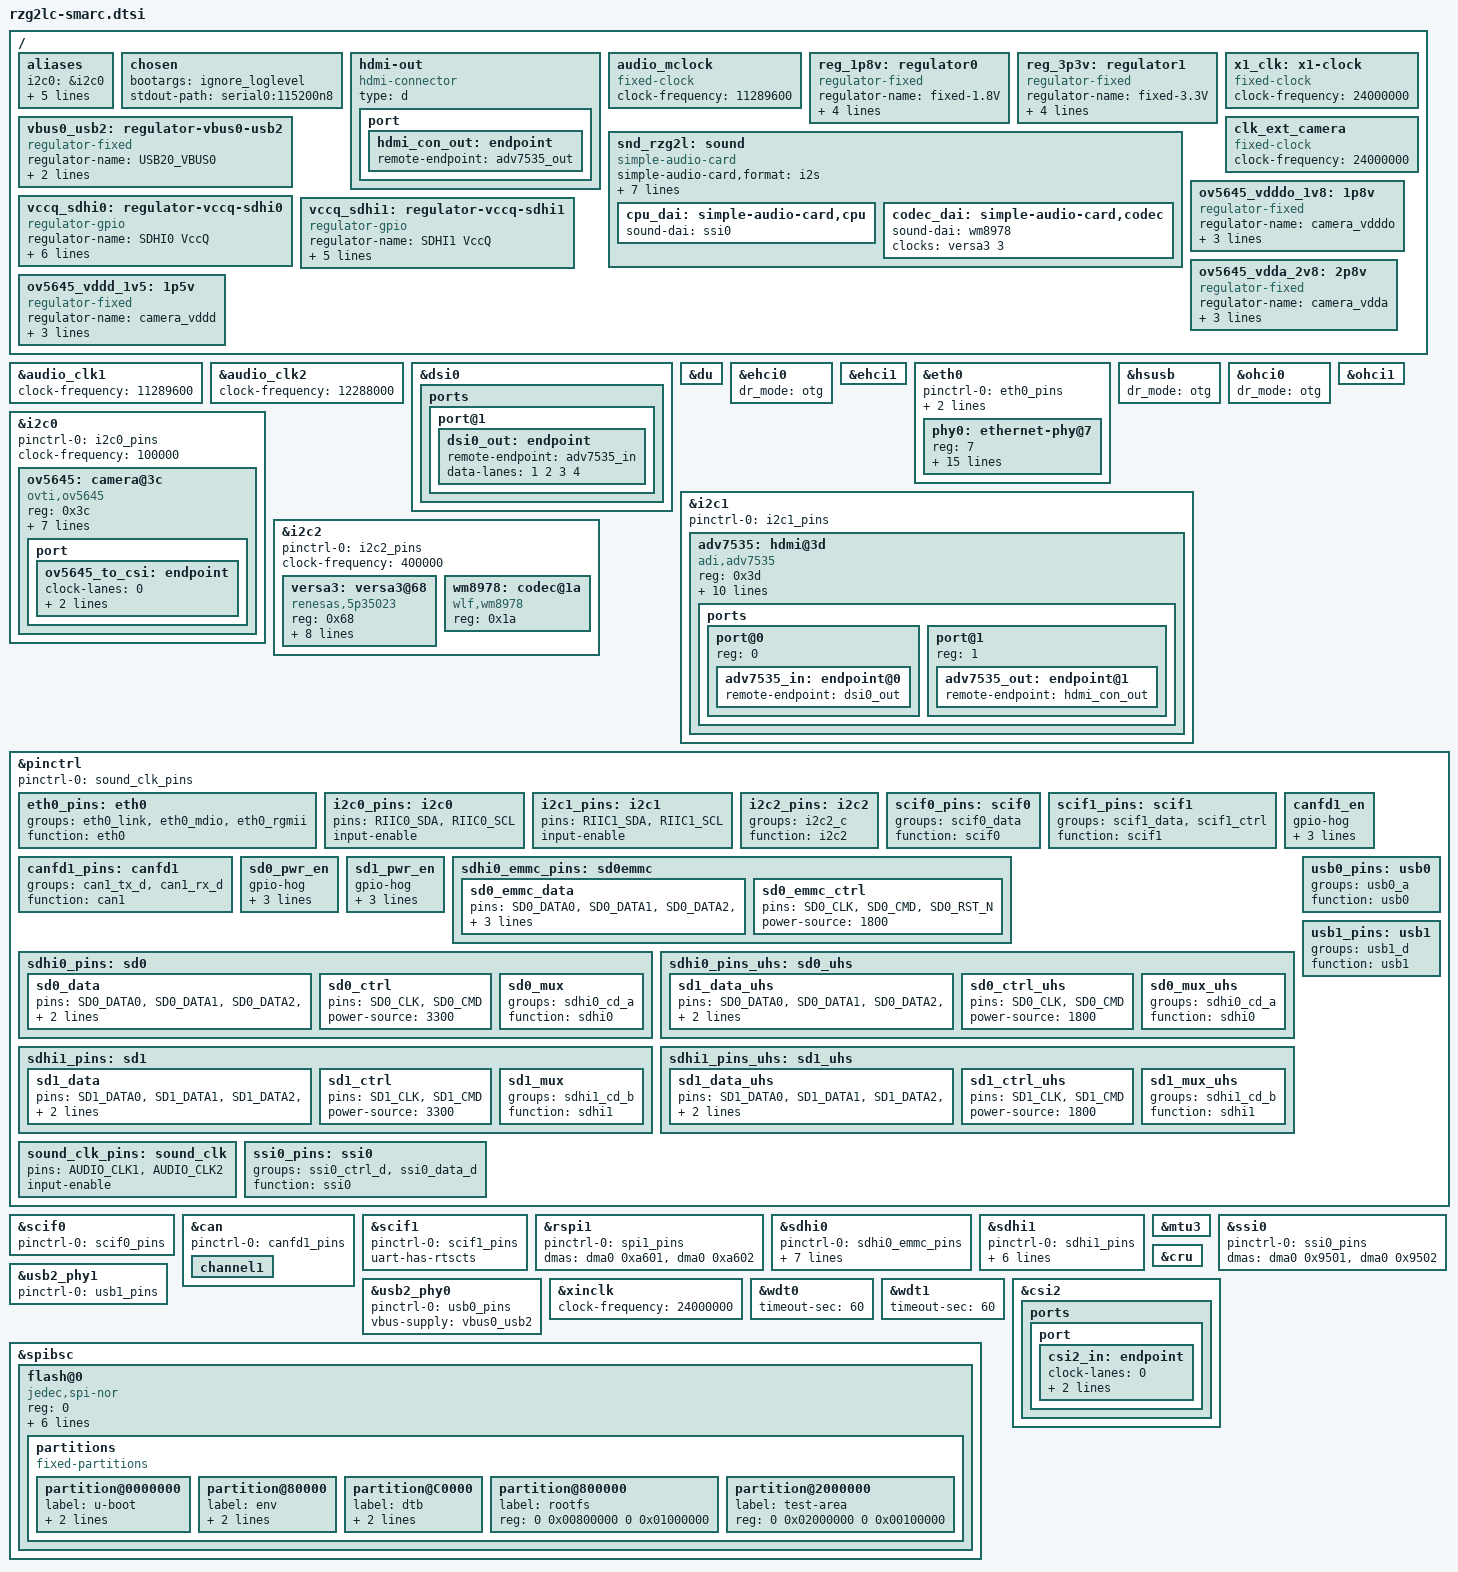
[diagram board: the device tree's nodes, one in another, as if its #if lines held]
// SPDX-License-Identifier: GPL-2.0
/*
 * Device Tree Source for the RZG2LC Evaluation Board Kit
 *
 * Copyright (C) 2021 Renesas Electronics Corp.
 */

#include <dt-bindings/pinctrl/pinctrl-rzg2l.h>
#include <dt-bindings/gpio/gpio.h>

/*
 * SSI-WM8978
 *
 * This command is required when Playback/Capture
 *
 *	amixer cset name='Left Input Mixer L2 Switch' on
 *	amixer cset name='Right Input Mixer R2 Switch' on
 *	amixer cset name='Headphone Playback Volume' 100
 *	amixer cset name='Input PGA Volume' 100
 *	amixer cset name='L2/R2 Boost Volume' 100
 *
 * ADV7535 Audio playback
 *	aplay -D hw:1,0 xxx.wav
 */

/*
 * DIP-Switch SW1 setting
 * 1 : High; 0: Low
 * SW1-2 : SW_SD0_DEV_SEL	(1: eMMC; 0: uSD)
 * SW1-3 : SW_SCIF_CAN		(1: CAN1; 0: SCIF1)
 * SW1-4 : SW_RSPI_CAN 		(1: CAN1; 0: RSPI1)
 * SW1-5 : SW_I2S0_I2S1		(1: I2S2 (HDMI audio); 0: I2S0)
 * Please change below MACROs corespondingly to SW1 setting
 */

#define SW_SD0_DEV_SEL	1
#define SW_SCIF_CAN	0
#if (SW_SCIF_CAN)
/*
 * Due to Hardware routing, SW_RSPI_CAN is always 0 when SW_SCIF_CAN is set to 1
 */
#define SW_RSPI_CAN	0
#else
/*
 * Please choose one of two below setting when SW_SCIF_CAN is set to 0.
 * Default value is 1.
 */
#define SW_RSPI_CAN     1
//#define SW_RSPI_CAN     0
#endif

#define SW_I2S0_I2S1	0

#if (SW_SCIF_CAN & SW_RSPI_CAN)
#error "Can not set 1 to both SW_SCIF_CAN and SW_RSPI_CAN due to Hardware."
#endif

/ {
	aliases {
		i2c0 = &i2c0;
		i2c1 = &i2c1;
		i2c2 = &i2c2;
		serial0 = &scif0;
#if (!SW_SCIF_CAN)
		serial1 = &scif1;
#endif
		ethernet0 = &eth0;
	};

	chosen {
		bootargs = "ignore_loglevel";
		stdout-path = "serial0:115200n8";
	};

	hdmi-out {
		compatible = "hdmi-connector";
		type = "d";

		port {
			hdmi_con_out: endpoint {
				remote-endpoint = <&adv7535_out>;
			};
		};
	};

	audio_mclock: audio_mclock {
		compatible = "fixed-clock";
		#clock-cells = <0>;
		clock-frequency = <11289600>;
	};

	reg_1p8v: regulator0 {
		compatible = "regulator-fixed";
		regulator-name = "fixed-1.8V";
		regulator-min-microvolt = <1800000>;
		regulator-max-microvolt = <1800000>;
		regulator-boot-on;
		regulator-always-on;
	};

	reg_3p3v: regulator1 {
		compatible = "regulator-fixed";

		regulator-name = "fixed-3.3V";
		regulator-min-microvolt = <3300000>;
		regulator-max-microvolt = <3300000>;
		regulator-boot-on;
		regulator-always-on;
	};

	vbus0_usb2: regulator-vbus0-usb2 {
		compatible = "regulator-fixed";

		regulator-name = "USB20_VBUS0";
		regulator-min-microvolt = <5000000>;
		regulator-max-microvolt = <5000000>;
	};

#if (SW_I2S0_I2S1)
	sound_card {
		compatible = "audio-graph-card";
		dais = <&ssi0>;
	};
#else
	snd_rzg2l: sound {
		compatible = "simple-audio-card";
		simple-audio-card,format = "i2s";
		simple-audio-card,bitclock-master = <&cpu_dai>;
		simple-audio-card,frame-master = <&cpu_dai>;
		simple-audio-card,mclk-fs = <256>;

		simple-audio-card,widgets = "Microphone", "Microphone Jack";
		simple-audio-card,routing =
			    "L2", "Mic Bias",
			    "R2", "Mic Bias",
			    "Mic Bias", "Microphone Jack";

		cpu_dai: simple-audio-card,cpu {
			sound-dai = <&ssi0>;
		};

		codec_dai: simple-audio-card,codec {
			sound-dai = <&wm8978>;
			clocks = <&versa3 3>;
		};
	};
#endif

	vccq_sdhi0: regulator-vccq-sdhi0 {
		compatible = "regulator-gpio";

		regulator-name = "SDHI0 VccQ";
		regulator-min-microvolt = <1800000>;
		regulator-max-microvolt = <3300000>;
		states = <3300000 1 1800000 0>;
		regulator-boot-on;
		gpios = <&pinctrl RZG2L_GPIO(39, 0) GPIO_ACTIVE_HIGH>;
		regulator-always-on;
	};

	vccq_sdhi1: regulator-vccq-sdhi1 {
		compatible = "regulator-gpio";

		regulator-name = "SDHI1 VccQ";
		regulator-min-microvolt = <1800000>;
		regulator-max-microvolt = <3300000>;

		gpios = <&pinctrl RZG2L_GPIO(39, 1) GPIO_ACTIVE_HIGH>;

		gpios-states = <1>;
		states = <3300000 1
			  1800000 0>;
	};

	x1_clk: x1-clock {
		compatible = "fixed-clock";
		#clock-cells = <0>;
		clock-frequency = <24000000>;
	};

	clk_ext_camera: clk_ext_camera {
		compatible = "fixed-clock";
		#clock-cells = <0>;
		clock-frequency = <24000000>;
	};

	ov5645_vdddo_1v8: 1p8v {
		compatible = "regulator-fixed";
		regulator-name = "camera_vdddo";
		regulator-min-microvolt = <1800000>;
		regulator-max-microvolt = <1800000>;
		regulator-always-on;
	};

	ov5645_vdda_2v8: 2p8v {
		compatible = "regulator-fixed";
		regulator-name = "camera_vdda";
		regulator-min-microvolt = <2800000>;
		regulator-max-microvolt = <2800000>;
		regulator-always-on;
	};

	ov5645_vddd_1v5: 1p5v {
		compatible = "regulator-fixed";
		regulator-name = "camera_vddd";
		regulator-min-microvolt = <1500000>;
		regulator-max-microvolt = <1500000>;
		regulator-always-on;
	};
};

&audio_clk1{
	clock-frequency = <11289600>;
};

&audio_clk2{
	clock-frequency = <12288000>;
};

&dsi0 {
	status = "okay";

	ports {
		port@1 {
			dsi0_out: endpoint {
				remote-endpoint = <&adv7535_in>;
				data-lanes = <1 2 3 4>;
			};
		};
	};
};

&du {
	status = "okay";
};

&ehci0 {
	dr_mode = "otg";
	status = "okay";
};

&ehci1 {
	status = "okay";
};

&eth0 {
	pinctrl-0 = <&eth0_pins>;
	pinctrl-names = "default";
	phy-handle = <&phy0>;
	phy-mode = "rgmii";
	status = "okay";

	phy0: ethernet-phy@7 {
		reg = <7>;
		rxc-skew-psec = <2400>;
		txc-skew-psec = <2400>;
		rxdv-skew-psec = <0>;
		txdv-skew-psec = <0>;
		rxd0-skew-psec = <0>;
		rxd1-skew-psec = <0>;
		rxd2-skew-psec = <0>;
		rxd3-skew-psec = <0>;
		txd0-skew-psec = <0>;
		txd1-skew-psec = <0>;
		txd2-skew-psec = <0>;
		txd3-skew-psec = <0>;

		interrupt-parent = <&pinctrl>;
		interrupts = <RZG2L_GPIO(0, 0) IRQ_TYPE_EDGE_FALLING>;
	};
};

&hsusb {
	dr_mode = "otg";
	status = "okay";
};

&i2c0 {
	pinctrl-0 = <&i2c0_pins>;
	pinctrl-names = "default";

	clock-frequency = <100000>;
	status = "okay";

	ov5645: camera@3c {
		compatible = "ovti,ov5645";
		reg = <0x3c>;
		clock-names = "xclk";
		clocks = <&clk_ext_camera>;
		clock-frequency = <24000000>;
		vdddo-supply = <&ov5645_vdddo_1v8>;
		vdda-supply = <&ov5645_vdda_2v8>;
		vddd-supply = <&ov5645_vddd_1v5>;
		enable-gpios = <&pinctrl RZG2L_GPIO(0, 1) GPIO_ACTIVE_HIGH>;
		reset-gpios = <&pinctrl RZG2L_GPIO(5, 2) GPIO_ACTIVE_LOW>;

		port {
			ov5645_to_csi: endpoint {
				clock-lanes = <0>;
				data-lanes = <1 2>;
				remote-endpoint = <&csi2_in>;
			};
		};
	};
};

&i2c1 {
	pinctrl-0 = <&i2c1_pins>;
	pinctrl-names = "default";

	status = "okay";

	adv7535: hdmi@3d {
		compatible = "adi,adv7535";
		reg = <0x3d>;

		avdd-supply = <&reg_1p8v>;
		dvdd-supply = <&reg_1p8v>;
		pvdd-supply = <&reg_1p8v>;
		a2vdd-supply = <&reg_1p8v>;
		v3p3-supply = <&reg_3p3v>;
		v1p2-supply = <&reg_1p8v>;

		interrupt-parent = <&pinctrl>;
		interrupts = <RZG2L_GPIO(43, 1) IRQ_TYPE_EDGE_FALLING>;

		adi,dsi-lanes = <4>;
		#sound-dai-cells = <0>;

		ports {
			#address-cells = <1>;
			#size-cells = <0>;

			port@0 {
				reg = <0>;
				adv7535_in: endpoint@0 {
					remote-endpoint = <&dsi0_out>;
				};
			};

			port@1 {
				reg = <1>;
				adv7535_out: endpoint@1 {
					remote-endpoint = <&hdmi_con_out>;
				};
			};

#if (SW_I2S0_I2S1)
			port@2 {
				reg = <2>;
				codec_endpoint: endpoint {
					remote-endpoint = <&i2s2_cpu_endpoint>;
				};
			};
#endif
		};
	};
};

&i2c2 {
	pinctrl-0 = <&i2c2_pins>;
	pinctrl-names = "default";

	clock-frequency = <400000>;
	status = "okay";

	versa3: versa3@68 {
		compatible = "renesas,5p35023";
		reg = <0x68>;
		#clock-cells = <1>;
		clocks = <&x1_clk>;
		clock-names = "x1";
		assigned-clocks = <&versa3 0>,
				   <&versa3 1>,
				   <&versa3 2>,
				   <&versa3 3>,
				   <&versa3 4>,
				   <&versa3 5>;
		assigned-clock-rates =	<12288000>, <25000000>,
					<12000000>, <11289600>,
					<11289600>, <24000000>;
		clock-divider-read-only = <1>, <1>, <1>, <1>, <1>;
		clock-flags = <2176>, <2176>, <2176>, <2052>, <2176>, <2048>;
	};

	wm8978: codec@1a {
		compatible = "wlf,wm8978";
		#sound-dai-cells = <0>;
		reg = <0x1a>;
	};
};

&ohci0 {
	dr_mode = "otg";
	status = "okay";
};

&ohci1 {
	status = "okay";
};

&pinctrl {
	pinctrl-0 = <&sound_clk_pins>;
	pinctrl-names = "default";

	eth0_pins: eth0 {
		groups = "eth0_link", "eth0_mdio", "eth0_rgmii";
		function = "eth0";
	};

	i2c0_pins: i2c0 {
		pins = "RIIC0_SDA", "RIIC0_SCL";
		input-enable;
	};

	i2c1_pins: i2c1 {
		pins = "RIIC1_SDA", "RIIC1_SCL";
		input-enable;
	};

	i2c2_pins: i2c2 {
		groups = "i2c2_c";
		function = "i2c2";
	};

	scif0_pins: scif0 {
		groups = "scif0_data";
		function = "scif0";
	};

#if (SW_SCIF_CAN)
	canfd1_pins: canfd1 {
		groups = "can1_tx_c", "can1_rx_c";
		function = "can1";
	};

	spi1_pins: rspi1 {
		groups = "rspi1_clk_b", "rspi1_data_b", "rspi1_ssl_b";
		function = "rspi1";
	};

#else
	scif1_pins: scif1 {
		groups = "scif1_data", "scif1_ctrl" ;
		function = "scif1";
	};

#if (SW_RSPI_CAN)
	canfd1_en {
		gpio-hog;
		gpios = <RZG2L_GPIO(44, 3) GPIO_ACTIVE_LOW>;
		output-high;
		line-name = "canfd1_en";
	};

	canfd1_pins: canfd1 {
		groups = "can1_tx_d", "can1_rx_d";
		function = "can1";
	};
#else
	spi1_pins: rspi1 {
		groups = "rspi1_clk_b", "rspi1_data_b", "rspi1_ssl_b";
		function = "rspi1";
	};
#endif
#endif

	sd0_pwr_en {
		gpio-hog;
		gpios = <RZG2L_GPIO(40, 2) GPIO_ACTIVE_HIGH>;
		output-high;
		line-name = "sd0_pwr_en";
	};

	sd1_pwr_en {
		gpio-hog;
		gpios = <RZG2L_GPIO(39, 2) GPIO_ACTIVE_HIGH>;
		output-high;
		line-name = "sd1_pwr_en";
	};

	sdhi0_emmc_pins: sd0emmc {
		sd0_emmc_data {
			pins = "SD0_DATA0", "SD0_DATA1", "SD0_DATA2", "SD0_DATA3",
			       "SD0_DATA4", "SD0_DATA5", "SD0_DATA6", "SD0_DATA7";
			power-source  = <1800>;
		};

		sd0_emmc_ctrl {
			pins = "SD0_CLK", "SD0_CMD", "SD0_RST_N";
			power-source  = <1800>;
		};
	};

	sdhi0_pins: sd0 {
		sd0_data {
			pins = "SD0_DATA0", "SD0_DATA1", "SD0_DATA2", "SD0_DATA3";
			power-source  = <3300>;
		};

		sd0_ctrl {
			pins = "SD0_CLK", "SD0_CMD";
			power-source  = <3300>;
		};

		sd0_mux {
			groups = "sdhi0_cd_a";
			function = "sdhi0";
		};
	};

	sdhi0_pins_uhs: sd0_uhs {
		sd1_data_uhs {
			pins = "SD0_DATA0", "SD0_DATA1", "SD0_DATA2", "SD0_DATA3";
			power-source  = <1800>;
		};

		sd0_ctrl_uhs {
			pins = "SD0_CLK", "SD0_CMD";
			power-source  = <1800>;
		};

		sd0_mux_uhs {
			groups = "sdhi0_cd_a";
			function = "sdhi0";
		};
	};

	sdhi1_pins: sd1 {
		sd1_data {
			pins = "SD1_DATA0", "SD1_DATA1", "SD1_DATA2", "SD1_DATA3";
			power-source  = <3300>;
		};

		sd1_ctrl {
			pins = "SD1_CLK", "SD1_CMD";
			power-source  = <3300>;
		};

		sd1_mux {
			groups = "sdhi1_cd_b";
			function = "sdhi1";
		};
	};

	sdhi1_pins_uhs: sd1_uhs {
		sd1_data_uhs {
			pins = "SD1_DATA0", "SD1_DATA1", "SD1_DATA2", "SD1_DATA3";
			power-source  = <1800>;
		};

		sd1_ctrl_uhs {
			pins = "SD1_CLK", "SD1_CMD";
			power-source  = <1800>;
		};

		sd1_mux_uhs {
			groups = "sdhi1_cd_b";
			function = "sdhi1";
		};
	};

	sound_clk_pins: sound_clk {
		pins = "AUDIO_CLK1", "AUDIO_CLK2";
		input-enable;
	};

	ssi0_pins: ssi0 {
		groups = "ssi0_ctrl_d", "ssi0_data_d";
		function = "ssi0";
	};

	/* USB Channel 0 */
	usb0_pins: usb0 {
		groups = "usb0_a";
		function = "usb0";
	};

	/* USB Channel 1 */
	usb1_pins: usb1 {
		groups = "usb1_d";
		function = "usb1";
	};
};

&scif0 {
	pinctrl-0 = <&scif0_pins>;
	pinctrl-names = "default";
	status = "okay";
};

#if ((SW_SCIF_CAN) || (SW_RSPI_CAN))
&can {
	pinctrl-0 = <&canfd1_pins>;
	pinctrl-names = "default";
	status = "okay";

	channel1 {
		status = "okay";
	};
};
#endif

#if (!SW_SCIF_CAN)
&scif1 {
	pinctrl-0 = <&scif1_pins>;
	pinctrl-names = "default";
	uart-has-rtscts;
	status = "okay";
};
#endif

#if ((!SW_RSPI_CAN) || SW_SCIF_CAN)
&rspi1 {
	pinctrl-0 = <&spi1_pins>;
	pinctrl-names = "default";
	status = "okay";
	dmas = <&dma0 0xa601>,
	       <&dma0 0xa602>;
	dma-names = "tx", "rx";
};
#endif

#if (SW_SD0_DEV_SEL)
&sdhi0 {
	pinctrl-0 = <&sdhi0_emmc_pins>;
	pinctrl-1 = <&sdhi0_emmc_pins>;
	pinctrl-names = "default", "state_uhs";

	vmmc-supply = <&reg_3p3v>;
	vqmmc-supply = <&reg_1p8v>;
	bus-width = <8>;
	mmc-hs200-1_8v;
	non-removable;
	fixed-emmc-driver-type = <1>;
	status = "okay";
};
#else
&sdhi0 {
	pinctrl-0 = <&sdhi0_pins>;
	pinctrl-1 = <&sdhi0_pins_uhs>;
	pinctrl-names = "default", "state_uhs";

	vmmc-supply = <&reg_3p3v>;
	vqmmc-supply = <&vccq_sdhi0>;

	bus-width = <4>;
	sd-uhs-sdr50;
	sd-uhs-sdr104;
	status = "okay";
};
#endif

&sdhi1 {
	pinctrl-0 = <&sdhi1_pins>;
	pinctrl-1 = <&sdhi1_pins_uhs>;
	pinctrl-names = "default", "state_uhs";

	vmmc-supply = <&reg_3p3v>;
	vqmmc-supply = <&vccq_sdhi1>;

	bus-width = <4>;
	sd-uhs-sdr50;
	sd-uhs-sdr104;
	status = "okay";
};

&mtu3 {
	status = "okay";
};

&ssi0 {
	pinctrl-0 = <&ssi0_pins>;
	pinctrl-names = "default";

	dmas = <&dma0 0x9501>,
	       <&dma0 0x9502>;
	dma-names = "tx", "rx";
	status = "okay";
#if (SW_I2S0_I2S1)
	ports {
		i2s2_port0: port@0 {
			i2s2_cpu_endpoint: endpoint {
				remote-endpoint = <&codec_endpoint>;
				dai-format = "i2s";
			};
		};
	};

#endif
};

&usb2_phy0 {
	pinctrl-0 = <&usb0_pins>;
	pinctrl-names = "default";

	vbus-supply = <&vbus0_usb2>;
	status = "okay";
};

&usb2_phy1 {
	pinctrl-0 = <&usb1_pins>;
	pinctrl-names = "default";

	status = "okay";
};

&xinclk {
	clock-frequency = <24000000>;
};

&wdt0 {
	status = "okay";
	timeout-sec = <60>;
};

&wdt1 {
	status = "okay";
	timeout-sec = <60>;
};

&spibsc {
status = "okay";

	flash@0 {
		compatible = "jedec,spi-nor";
		reg = <0>;
		spi-max-frequency = <30000000>;

		spi-tx-bus-width = <1>;
		spi-rx-bus-width = <1>;

		/* SPI Mode 3 */
		spi-cpol;
		spi-cpha;
		m25p,fast-read;
		partitions {
			compatible = "fixed-partitions";
			#address-cells = <2>;
			#size-cells = <2>;

			partition@0000000 {
				label = "u-boot";
				reg = <0 0x00000000 0 0x80000>;
				read-only;
			};
			partition@80000 {
				label = "env";
				reg = <0 0x00080000 0 0x40000>;
				read-only;
			};
			partition@C0000 {
				label = "dtb";
				reg = <0 0x000C0000 0 0x40000>;
				read-only;
			};
			partition@800000 {
				label = "rootfs";
				/* 16MB @ 8MB offset in SPI Flash */
				reg = <0 0x00800000 0 0x01000000>;
			};
			partition@2000000 {
				label = "test-area";
				reg = <0 0x02000000 0 0x00100000>;
			};
		};
	};
};

&cru {
	status = "okay";
};

&csi2 {
	status = "okay";

	ports {
		port {
			csi2_in: endpoint {
				clock-lanes = <0>;
				data-lanes = <1 2>;
				remote-endpoint = <&ov5645_to_csi>;
			};
		};
	};
};
